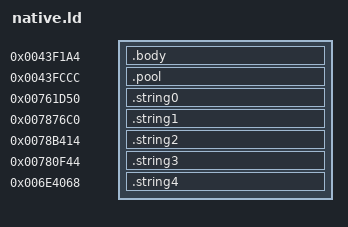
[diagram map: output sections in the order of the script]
ENTRY(native_lv_obj_refr_size)
SECTIONS {
.body 0x43f1a4 : {*(.body)}
.pool 0x43fccc : {*(.pool)}
.string0 0x761d50 : {*(.string0)}
.string1 0x7876c0 : {*(.string1)}
.string2 0x78b414 : {*(.string2)}
.string3 0x780f44 : {*(.string3)}
.string4 0x6e4068 : {*(.string4)}
}
